# STM32F30xxx register map
File version: 1.0
Registers are 32-bit, read-write, reset 0x0 unless marked. A register's access mark holds for its fields unless they carry their own. Offsets are from the block's base; [hi:lo] are bit positions.

## COMP — Comparator
Base 0x4001001C
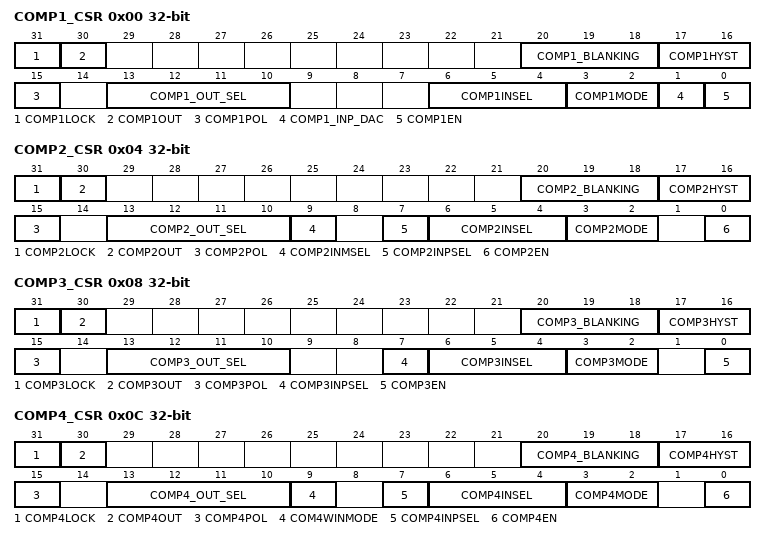
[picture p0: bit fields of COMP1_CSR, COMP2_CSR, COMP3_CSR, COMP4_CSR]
0x00 COMP1_CSR access per field — control and status register
  [31] COMP1LOCK rw — Comparator 1 lock
  [30] COMP1OUT ro — Comparator 1 output
  [20:18] COMP1_BLANKING rw — Comparator 1 blanking source
  [17:16] COMP1HYST rw — Comparator 1 hysteresis
  [15] COMP1POL rw — Comparator 1 output polarity
  [13:10] COMP1_OUT_SEL rw — Comparator 1 output selection
  [6:4] COMP1INSEL rw — Comparator 1 inverting input selection
  [3:2] COMP1MODE rw — Comparator 1 mode
  [1] COMP1_INP_DAC rw
  [0] COMP1EN rw — Comparator 1 enable
0x04 COMP2_CSR access per field — control and status register
  [31] COMP2LOCK rw — Comparator 2 lock
  [30] COMP2OUT ro — Comparator 2 output
  [20:18] COMP2_BLANKING rw — Comparator 2 blanking source
  [17:16] COMP2HYST rw — Comparator 2 hysteresis
  [15] COMP2POL rw — Comparator 2 output polarity
  [13:10] COMP2_OUT_SEL rw — Comparator 2 output selection
  [9] COMP2INMSEL rw — Comparator 1inverting input selection
  [7] COMP2INPSEL rw — Comparator 2 non inverted input selection
  [6:4] COMP2INSEL rw — Comparator 2 inverting input selection
  [3:2] COMP2MODE rw — Comparator 2 mode
  [0] COMP2EN rw — Comparator 2 enable
0x08 COMP3_CSR access per field — control and status register
  [31] COMP3LOCK rw — Comparator 3 lock
  [30] COMP3OUT ro — Comparator 3 output
  [20:18] COMP3_BLANKING rw — Comparator 3 blanking source
  [17:16] COMP3HYST rw — Comparator 3 hysteresis
  [15] COMP3POL rw — Comparator 3 output polarity
  [13:10] COMP3_OUT_SEL rw — Comparator 3 output selection
  [7] COMP3INPSEL rw — Comparator 3 non inverted input selection
  [6:4] COMP3INSEL rw — Comparator 3 inverting input selection
  [3:2] COMP3MODE rw — Comparator 3 mode
  [0] COMP3EN rw — Comparator 3 enable
0x0C COMP4_CSR access per field — control and status register
  [31] COMP4LOCK rw — Comparator 4 lock
  [30] COMP4OUT ro — Comparator 4 output
  [20:18] COMP4_BLANKING rw — Comparator 4 blanking source
  [17:16] COMP4HYST rw — Comparator 4 hysteresis
  [15] COMP4POL rw — Comparator 4 output polarity
  [13:10] COMP4_OUT_SEL rw — Comparator 4 output selection
  [9] COM4WINMODE rw — Comparator 4 window mode
  [7] COMP4INPSEL rw — Comparator 4 non inverted input selection
  [6:4] COMP4INSEL rw — Comparator 4 inverting input selection
  [3:2] COMP4MODE rw — Comparator 4 mode
  [0] COMP4EN rw — Comparator 4 enable
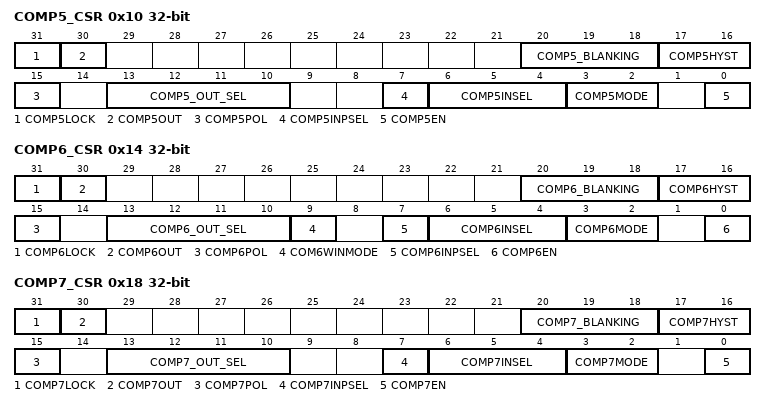
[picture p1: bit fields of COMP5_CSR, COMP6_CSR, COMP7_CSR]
0x10 COMP5_CSR access per field — control and status register
  [31] COMP5LOCK rw — Comparator 5 lock
  [30] COMP5OUT ro — Comparator51 output
  [20:18] COMP5_BLANKING rw — Comparator 5 blanking source
  [17:16] COMP5HYST rw — Comparator 5 hysteresis
  [15] COMP5POL rw — Comparator 5 output polarity
  [13:10] COMP5_OUT_SEL rw — Comparator 5 output selection
  [7] COMP5INPSEL rw — Comparator 5 non inverted input selection
  [6:4] COMP5INSEL rw — Comparator 5 inverting input selection
  [3:2] COMP5MODE rw — Comparator 5 mode
  [0] COMP5EN rw — Comparator 5 enable
0x14 COMP6_CSR access per field — control and status register
  [31] COMP6LOCK rw — Comparator 6 lock
  [30] COMP6OUT ro — Comparator 6 output
  [20:18] COMP6_BLANKING rw — Comparator 6 blanking source
  [17:16] COMP6HYST rw — Comparator 6 hysteresis
  [15] COMP6POL rw — Comparator 6 output polarity
  [13:10] COMP6_OUT_SEL rw — Comparator 6 output selection
  [9] COM6WINMODE rw — Comparator 6 window mode
  [7] COMP6INPSEL rw — Comparator 6 non inverted input selection
  [6:4] COMP6INSEL rw — Comparator 6 inverting input selection
  [3:2] COMP6MODE rw — Comparator 6 mode
  [0] COMP6EN rw — Comparator 6 enable
0x18 COMP7_CSR access per field — control and status register
  [31] COMP7LOCK rw — Comparator 7 lock
  [30] COMP7OUT ro — Comparator 7 output
  [20:18] COMP7_BLANKING rw — Comparator 7 blanking source
  [17:16] COMP7HYST rw — Comparator 7 hysteresis
  [15] COMP7POL rw — Comparator 7 output polarity
  [13:10] COMP7_OUT_SEL rw — Comparator 7 output selection
  [7] COMP7INPSEL rw — Comparator 7 non inverted input selection
  [6:4] COMP7INSEL rw — Comparator 7 inverting input selection
  [3:2] COMP7MODE rw — Comparator 7 mode
  [0] COMP7EN rw — Comparator 7 enable
